# nrf9120_mlm1_modem register map
Vendor: Nordic Semiconductor; Series: nrf91; File version: 1
CPU: CM4 r0p1, little endian, MPU, no FPU, 3 interrupt priority bits
Registers are 32-bit, read-write, reset 0x0 unless marked. A register's access mark holds for its fields unless they carry their own. Offsets are from the block's base; [hi:lo] are bit positions; {n}, {i} and the like mark numbered series; 'fields as' and 'values as' point back to an identical list.

## AESL2 — AES-128 HW accelerator for LTE L2 security and MAC
Base 0x40042000
0x00 TASKS_START_GATHER wo — Start input DMA
  [0] TASKS_START_GATHER
    1=Trigger task
0x04 TASKS_STOP_GATHER wo — Stop input DMA
  [0] TASKS_STOP_GATHER
    1=Trigger task
0x08 TASKS_START_SCATTER wo — Start output DMA
  [0] TASKS_START_SCATTER
    1=Trigger task
0x0C TASKS_STOP_SCATTER wo — Stop output DMA
  [0] TASKS_STOP_SCATTER
    1=Trigger task
0x10 TASKS_INITIALIZE_AES wo — New keys (and IV) ready to be used, reset keybytes, ivbytes
  [0] TASKS_INITIALIZE_AES
    1=Trigger task
0x14 TASKS_START_OPERATION wo — Start cipher / MAC calculation depending on MODE
  [0] TASKS_START_OPERATION
    1=Trigger task
0x18 TASKS_FINALIZE_MAC wo — Finalize MAC calculation
  [0] TASKS_FINALIZE_MAC
    1=Trigger task
0x1C TASKS_RESET wo — Stop all transfers and crypto operations (initialize)
  [0] TASKS_RESET
    1=Trigger task
0x70 TaskZeroPenalty_PCP_1 wo — TaskZeroPenalty register for PCP 1
  [0] ZERO_PENALTY
    1=SET_ZERO_PENALTY
0x74 TaskFullPenalty_PCP_1 wo — TaskFullPenalty register for PCP 1
  [0] FULL_PENALTY
    1=SET_FULL_PENALTY
0x78 TaskZeroPenalty_PCP_0 wo — TaskZeroPenalty register for PCP 0
  [0] ZERO_PENALTY
    1=SET_ZERO_PENALTY
0x7C TaskFullPenalty_PCP_0 wo — TaskFullPenalty register for PCP 0
  [0] FULL_PENALTY
    1=SET_FULL_PENALTY
0x100 EVENTS_GATHER_STARTED — Input DMA started
  [0] EVENTS_GATHER_STARTED
    0=NotGenerated (Event not generated); 1=Generated (Event generated)
0x104 EVENTS_GATHER_DONE — Input DMA done
  [0] EVENTS_GATHER_DONE
    values as EVENTS_GATHER_STARTED.EVENTS_GATHER_STARTED
0x108 EVENTS_SCATTER_STARTED — Output DMA started
  [0] EVENTS_SCATTER_STARTED
    values as EVENTS_GATHER_STARTED.EVENTS_GATHER_STARTED
0x10C EVENTS_SCATTER_DONE — Output DMA done
  [0] EVENTS_SCATTER_DONE
    values as EVENTS_GATHER_STARTED.EVENTS_GATHER_STARTED
0x110 EVENTS_IV_READY — IV received (ivbytes == 16)
  [0] EVENTS_IV_READY
    values as EVENTS_GATHER_STARTED.EVENTS_GATHER_STARTED
0x114 EVENTS_AES_INITIALIZED — New keys and IV taken into use
  [0] EVENTS_AES_INITIALIZED
    values as EVENTS_GATHER_STARTED.EVENTS_GATHER_STARTED
0x118 EVENTS_MESSAGE_READY — LENGTH == 0
  [0] EVENTS_MESSAGE_READY
    values as EVENTS_GATHER_STARTED.EVENTS_GATHER_STARTED
0x11C EVENTS_MAC_READY — MAC calculated
  [0] EVENTS_MAC_READY
    values as EVENTS_GATHER_STARTED.EVENTS_GATHER_STARTED
0x120 EVENTS_RESETTED — Resetted (all transfers and crypto operations stopped)
  [0] EVENTS_RESETTED
    values as EVENTS_GATHER_STARTED.EVENTS_GATHER_STARTED
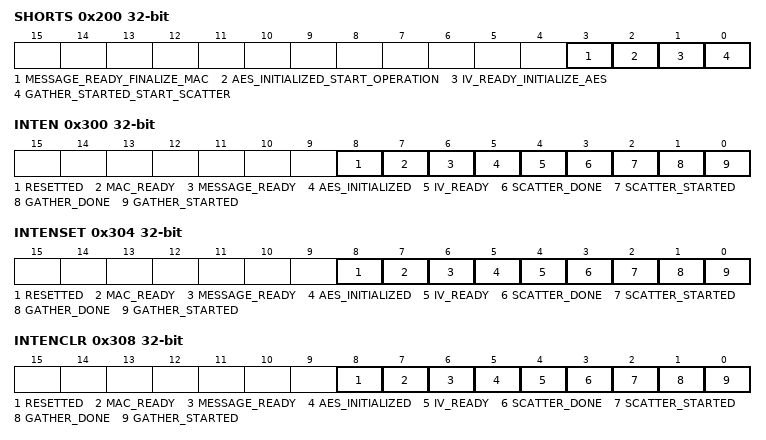
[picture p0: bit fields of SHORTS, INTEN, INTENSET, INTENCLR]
0x200 SHORTS — Shortcuts between local events and tasks
  [all] fields
    0=Disabled (Disable shortcut); 1=Enabled (Enable shortcut)
  [3] MESSAGE_READY_FINALIZE_MAC — Shortcut between event MESSAGE_READY and task FINALIZE_MAC
  [2] AES_INITIALIZED_START_OPERATION — Shortcut between event AES_INITIALIZED and task START_OPERATION
  [1] IV_READY_INITIALIZE_AES — Shortcut between event IV_READY and task INITIALIZE_AES
  [0] GATHER_STARTED_START_SCATTER — Shortcut between event GATHER_STARTED and task START_SCATTER
0x300 INTEN — Enable or disable interrupt
  [all] fields
    0=Disabled; 1=Enabled
  [8] RESETTED — Enable or disable interrupt for event RESETTED
  [7] MAC_READY — Enable or disable interrupt for event MAC_READY
  [6] MESSAGE_READY — Enable or disable interrupt for event MESSAGE_READY
  [5] AES_INITIALIZED — Enable or disable interrupt for event AES_INITIALIZED
  [4] IV_READY — Enable or disable interrupt for event IV_READY
  [3] SCATTER_DONE — Enable or disable interrupt for event SCATTER_DONE
  [2] SCATTER_STARTED — Enable or disable interrupt for event SCATTER_STARTED
  [1] GATHER_DONE — Enable or disable interrupt for event GATHER_DONE
  [0] GATHER_STARTED — Enable or disable interrupt for event GATHER_STARTED
0x304 INTENSET — Enable interrupt
  [all] fields
    on read: 0=Disabled (Read: Disabled); 1=Enabled (Read: Enabled) | on write: 1=Set (Enable)
  [8] RESETTED — Write '1' to enable interrupt for event RESETTED
  [7] MAC_READY — Write '1' to enable interrupt for event MAC_READY
  [6] MESSAGE_READY — Write '1' to enable interrupt for event MESSAGE_READY
  [5] AES_INITIALIZED — Write '1' to enable interrupt for event AES_INITIALIZED
  [4] IV_READY — Write '1' to enable interrupt for event IV_READY
  [3] SCATTER_DONE — Write '1' to enable interrupt for event SCATTER_DONE
  [2] SCATTER_STARTED — Write '1' to enable interrupt for event SCATTER_STARTED
  [1] GATHER_DONE — Write '1' to enable interrupt for event GATHER_DONE
  [0] GATHER_STARTED — Write '1' to enable interrupt for event GATHER_STARTED
0x308 INTENCLR — Disable interrupt
  [all] fields
    on read: 0=Disabled (Read: Disabled); 1=Enabled (Read: Enabled) | on write: 1=Clear (Disable)
  [8] RESETTED — Write '1' to disable interrupt for event RESETTED
  [7] MAC_READY — Write '1' to disable interrupt for event MAC_READY
  [6] MESSAGE_READY — Write '1' to disable interrupt for event MESSAGE_READY
  [5] AES_INITIALIZED — Write '1' to disable interrupt for event AES_INITIALIZED
  [4] IV_READY — Write '1' to disable interrupt for event IV_READY
  [3] SCATTER_DONE — Write '1' to disable interrupt for event SCATTER_DONE
  [2] SCATTER_STARTED — Write '1' to disable interrupt for event SCATTER_STARTED
  [1] GATHER_DONE — Write '1' to disable interrupt for event GATHER_DONE
  [0] GATHER_STARTED — Write '1' to disable interrupt for event GATHER_STARTED
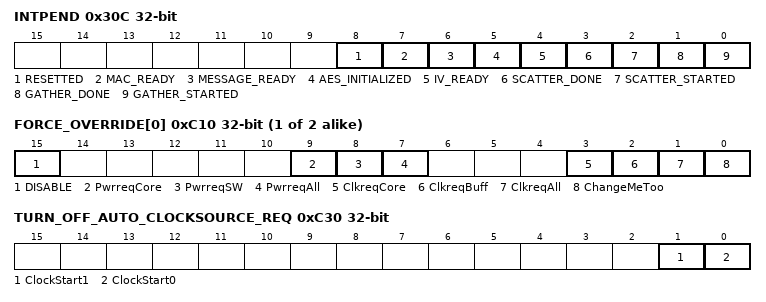
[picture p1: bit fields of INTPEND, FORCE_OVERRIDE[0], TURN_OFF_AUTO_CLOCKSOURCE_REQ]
0x30C INTPEND ro — Pending interrupts
  [all] fields
    on read: 0=NotPending (Read: Not pending); 1=Pending (Read: Pending)
  [8] RESETTED — Read pending status of interrupt for event RESETTED
  [7] MAC_READY — Read pending status of interrupt for event MAC_READY
  [6] MESSAGE_READY — Read pending status of interrupt for event MESSAGE_READY
  [5] AES_INITIALIZED — Read pending status of interrupt for event AES_INITIALIZED
  [4] IV_READY — Read pending status of interrupt for event IV_READY
  [3] SCATTER_DONE — Read pending status of interrupt for event SCATTER_DONE
  [2] SCATTER_STARTED — Read pending status of interrupt for event SCATTER_STARTED
  [1] GATHER_DONE — Read pending status of interrupt for event GATHER_DONE
  [0] GATHER_STARTED — Read pending status of interrupt for event GATHER_STARTED
0x400 LENGTH — Keystream length in bits (Cipher), message length in bits (MAC)
0x404 MODE — Mode: 0 == Cipher, 1 == MAC
  [0] MODE
    0=Ciphering mode; 1=MAC (CMAC mode)
0x600 MAC ro — EIA2 MAC
0x800 INJOBPTR — Input job pointer
0x900 OUTJOBPTR — Output job pointer
{0xC00+4i} PENALTY_REG[{i}] (i=0..1) — Description collection: Penalty register for PCP n
  [1:0] Penalty — Penalty Level
    0=Full (Auto 0) Full penalty)); 1=Semi1 ((Auto 1) Semi (power on, clock off)); 2=Semi0 ((Auto 2) Semi (power on, clock core on, clock buffer off)); 3=Zero ((Auto 3) Zero penalty)
{0xC10+4i} FORCE_OVERRIDE[{i}] (i=0..1) — Description collection: Force override register for PCP n
  [15] DISABLE
    0=zero (all forcing disabled); 1=one (all forcing enabled)
  [9] PwrreqCore
    0=zero (powerRequest.core = 0); 1=one (powerRequest.core = 1)
  [8] PwrreqSW
    0=zero (powerRequest.switch = 0); 1=one (powerRequest.switch = 1)
  [7] PwrreqAll
    0=zero (All clock forcing disabled); 1=one (All clock forcing enabled)
  [3] ClkreqCore
    0=zero (clockRequest.core = 0); 1=one (clockRequest.core = 1)
  [2] ClkreqBuff
    0=zero (clockRequest.buff = 0); 1=one (clockRequest.buff = 1)
  [1] ClkreqAll
    0=zero (clockRequest.switch = 0); 1=one (clockRequest.switch = 1)
  [0] ChangeMeToo
    0=zero (clockRequest.switch_a = 0); 1=one (clockRequest.switch_a = 1)
0xC30 TURN_OFF_AUTO_CLOCKSOURCE_REQ — Turn of the automatic clock request.
  [1] ClockStart1
    0=zero (normal clock start for PCP 1); 1=one (turn off normal clock start for PCP 1)
  [0] ClockStart0
    0=zero (normal clock start for PCP 0); 1=one (turn off normal clock start for PCP 0)
